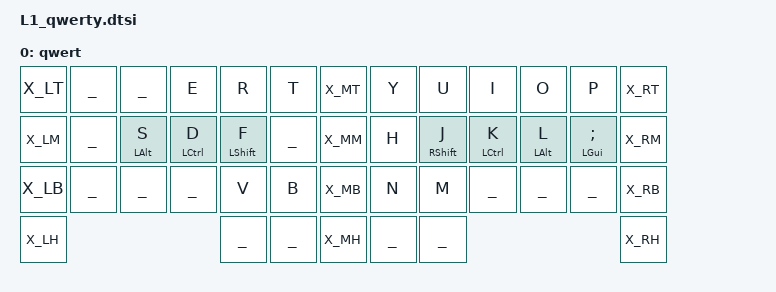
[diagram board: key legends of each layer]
/{
    keymap {
        compatible = "zmk,keymap";

        qwert {
            bindings = <
//╭──────╮ ╭─────────────┬─────────────┬─────────────┬─────────────┬─────────────╮ ╭──────╮ ╭─────────────┬─────────────┬─────────────┬─────────────┬─────────────╮ ╭──────╮
    X_LT     ___           ___           &kp E         &kp R         &kp T           X_MT     &kp Y         &kp U         &kp I         &kp O         &kp P         X_RT
//├──────┤ ├─────────────┼─────────────┼─────────────┼─────────────┼─────────────┤ ├──────┤ ├─────────────┼─────────────┼─────────────┼─────────────┼─────────────┤ ├──────┤
    X_LM     ___           &hml LALT S   &hml LCTRL D  &hml LSHFT F  ___             X_MM     &kp H         &hmr RSHFT J  &hmr LCTRL K  &hmr LALT L   &hmr LGUI SEMI  X_RM
//├──────┤ ├─────────────┼─────────────┼─────────────┼─────────────┼─────────────┤ ├──────┤ ├─────────────┼─────────────┼─────────────┼─────────────┼─────────────┤ ├──────┤
    X_LB     ___           ___           ___           &kp V         &kp B           X_MB     &kp N         &kp M         ___           ___           ___             X_RB
//├──────┤ ╰─────────────┼─────────────┴─────────────┼─────────────┼─────────────┤ ├──────┤ ├─────────────┼─────────────┼─────────────┴───────────────────────────╯ ├──────┤
    X_LH                                               ___           ___             X_MH     ___           ___                                                       X_RH
//╰──────╯                                           ╰─────────────┴─────────────╯ ╰──────╯ ╰─────────────┴─────────────╯                                           ╰──────╯
            >;
        };
    };
};
